# STM32H533xx register map
File version: 1.0
Registers are 32-bit, read-write, reset 0x0 unless marked. A register's access mark holds for its fields unless they carry their own. Offsets are from the block's base; [hi:lo] are bit positions; lines under a group give offsets from that group; {n}, {i} and the like mark numbered series.

## ADC12_COMMON
Base 0x42028300
Same registers: ADC12_COMMON_S 0x52028300
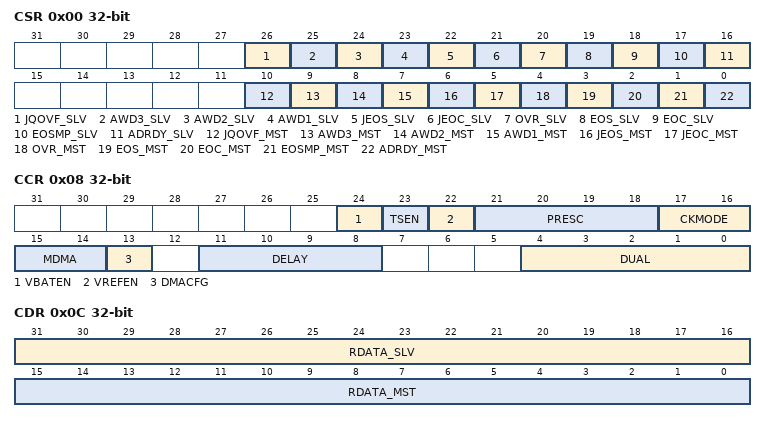
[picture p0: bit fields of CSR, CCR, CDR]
0x00 CSR — ADC common status register
  [26] JQOVF_SLV — ADC multimode slave group injected contexts queue overflow flag
  [25] AWD3_SLV — ADC multimode slave analog watchdog 3 flag
  [24] AWD2_SLV — ADC multimode slave analog watchdog 2 flag
  [23] AWD1_SLV — ADC multimode slave analog watchdog 1 flag
  [22] JEOS_SLV — ADC multimode slave group injected end of sequence conversions flag
  [21] JEOC_SLV — ADC multimode slave group injected end of unitary conversion flag
  [20] OVR_SLV — ADC multimode slave group regular overrun flag
  [19] EOS_SLV — ADC multimode slave group regular end of sequence conversions flag
  [18] EOC_SLV — ADC multimode slave group regular end of unitary conversion flag
  [17] EOSMP_SLV — ADC multimode slave group regular end of sampling flag
  [16] ADRDY_SLV — ADC multimode slave ready flag
  [10] JQOVF_MST — ADC multimode master group injected contexts queue overflow flag
  [9] AWD3_MST — ADC multimode master analog watchdog 3 flag
  [8] AWD2_MST — ADC multimode master analog watchdog 2 flag
  [7] AWD1_MST — ADC multimode master analog watchdog 1 flag
  [6] JEOS_MST — ADC multimode master group injected end of sequence conversions flag
  [5] JEOC_MST — ADC multimode master group injected end of unitary conversion flag
  [4] OVR_MST — ADC multimode master group regular overrun flag
  [3] EOS_MST — ADC multimode master group regular end of sequence conversions flag
  [2] EOC_MST — ADC multimode master group regular end of unitary conversion flag
  [1] EOSMP_MST — ADC multimode master group regular end of sampling flag
  [0] ADRDY_MST — ADC multimode master ready flag
0x08 CCR — ADC common configuration register
  [24] VBATEN — ADC internal path to battery voltage enable
  [23] TSEN — ADC internal path to temperature sensor enable
  [22] VREFEN — ADC internal path to VrefInt enable
  [21:18] PRESC — ADC common clock prescaler, only for clock source asynchronous
  [17:16] CKMODE — ADC common clock source and prescaler (prescaler only for clock source synchronous)
  [15:14] MDMA — ADC multimode DMA transfer enable
  [13] DMACFG — ADC multimode DMA transfer configuration
  [11:8] DELAY — ADC multimode delay between 2 sampling phases
    0=DELAY_1CYCLE; {v}=DELAY_{v+1}CYCLES (v=1..11)
  [4:0] DUAL — ADC multimode mode selection
    0=INDEPENDENT; 6=DUAL_REG_SIMULT; 7=DUAL_REG_INTERL; 5=DUAL_INJ_SIMULT; 9=DUAL_INJ_ALTERN; 1=DUAL_REG_SIM_INJ_SIM; 2=DUAL_REG_SIM_INJ_ALT; 3=DUAL_REG_INT_INJ_SIM
0x0C CDR — ADC common group regular data register
  [31:16] RDATA_SLV — ADC multimode slave group regular conversion data
  [15:0] RDATA_MST — ADC multimode master group regular conversion data

## DCMI
Base 0x4202C000
Same registers: DCMI_S 0x5202C000
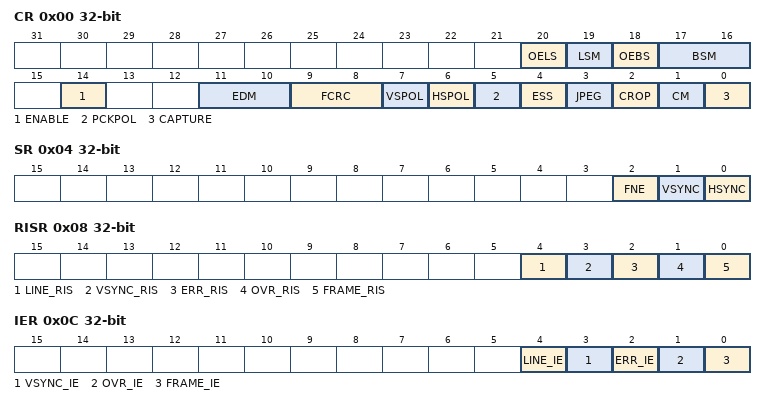
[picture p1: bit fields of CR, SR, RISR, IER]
0x00 CR — DCMI control register 1
  [20] OELS
  [19] LSM
  [18] OEBS
  [17:16] BSM
  [14] ENABLE
  [11:10] EDM — DCMI Extended data mode EDM[1:0]
  [9:8] FCRC — DCMI Frame capture rate control FCRC[1:0]
  [7] VSPOL
  [6] HSPOL
  [5] PCKPOL
  [4] ESS
  [3] JPEG
  [2] CROP
  [1] CM
  [0] CAPTURE
0x04 SR — DCMI status register
  [2] FNE, [1] VSYNC, [0] HSYNC
0x08 RISR — DCMI raw interrupt status register
  [4] LINE_RIS, [3] VSYNC_RIS, [2] ERR_RIS, [1] OVR_RIS, [0] FRAME_RIS
0x0C IER — DCMI interrupt enable register
  [4] LINE_IE, [3] VSYNC_IE, [2] ERR_IE, [1] OVR_IE, [0] FRAME_IE
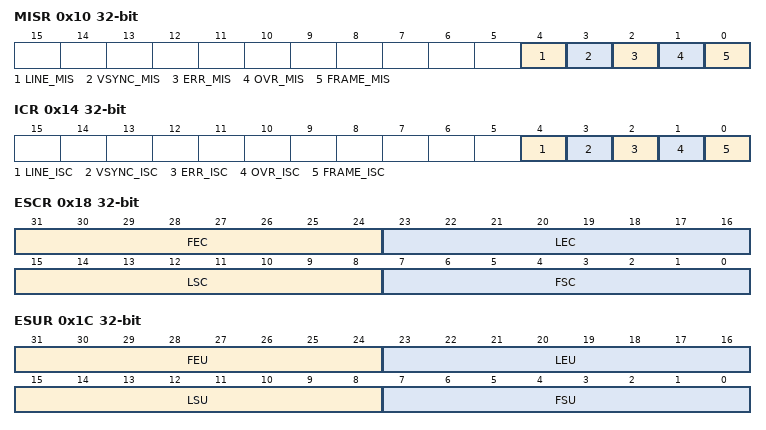
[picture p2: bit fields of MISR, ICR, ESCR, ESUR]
0x10 MISR — DCMI masked interrupt status register
  [4] LINE_MIS, [3] VSYNC_MIS, [2] ERR_MIS, [1] OVR_MIS, [0] FRAME_MIS
0x14 ICR — DCMI interrupt clear register
  [4] LINE_ISC, [3] VSYNC_ISC, [2] ERR_ISC, [1] OVR_ISC, [0] FRAME_ISC
0x18 ESCR — DCMI embedded synchronization code register
  [31:24] FEC, [23:16] LEC, [15:8] LSC, [7:0] FSC
0x1C ESUR — DCMI embedded synchronization unmask register
  [31:24] FEU, [23:16] LEU, [15:8] LSU, [7:0] FSU
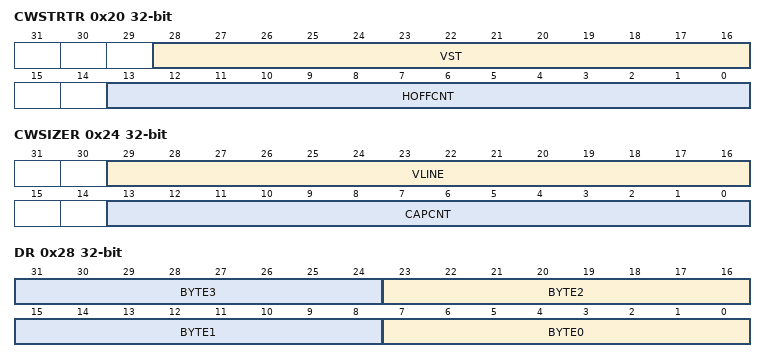
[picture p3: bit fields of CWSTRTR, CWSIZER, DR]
0x20 CWSTRTR — DCMI crop window start
  [28:16] VST, [13:0] HOFFCNT
0x24 CWSIZER — DCMI crop window size
  [29:16] VLINE, [13:0] CAPCNT
0x28 DR — DCMI data register
  [8n+7:8n] BYTE{n} (n=0..3)
